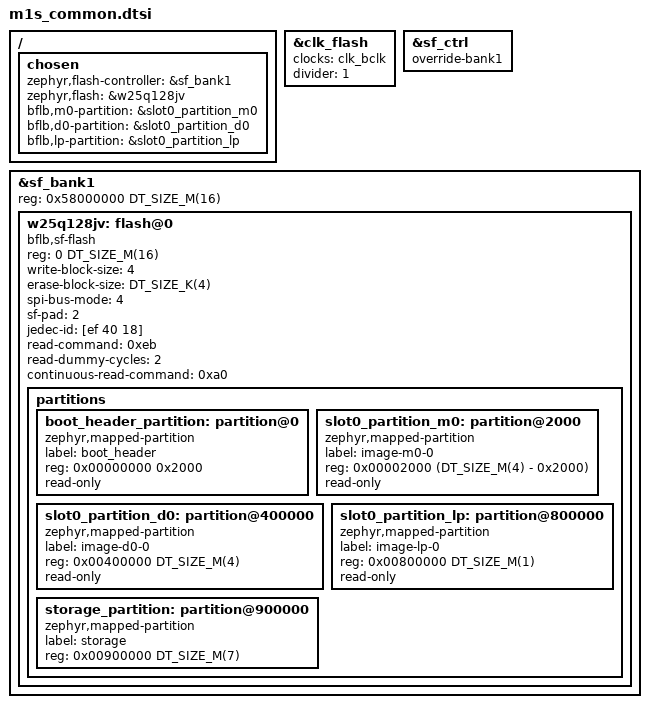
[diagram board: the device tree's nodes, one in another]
/*
 * Copyright The Zephyr Project Contributors
 *
 * SPDX-License-Identifier: Apache-2.0
 */

#include "m1s-pinctrl.dtsi"

/ {
	chosen {
		zephyr,flash-controller = &sf_bank1;
		zephyr,flash = &w25q128jv;
		bflb,m0-partition = &slot0_partition_m0;
		bflb,d0-partition = &slot0_partition_d0;
		bflb,lp-partition = &slot0_partition_lp;
	};
};

&clk_flash {
	clocks = <&clk_bclk>;
	divider = <1>;
};

&sf_ctrl {
	override-bank1;
};

&sf_bank1 {
	reg = <0x58000000 DT_SIZE_M(16)>;
	ranges = <0x0 0x58000000 DT_SIZE_M(16)>;

	w25q128jv: flash@0 {
		compatible = "bflb,sf-flash", "soc-nv-flash";
		reg = <0 DT_SIZE_M(16)>;
		ranges;
		#address-cells = <1>;
		#size-cells = <1>;
		write-block-size = <4>;
		erase-block-size = <DT_SIZE_K(4)>;

		spi-bus-mode = <4>;
		sf-pad = <2>;
		jedec-id = [ef 40 18];

		/* The flash equipped on M1S modules doesn't support useful SFDP, and the
		 * flash header doesn't provide a working configuration.
		 * Manually set configuration for best performance.
		 */
		read-command = <0xeb>;
		read-dummy-cycles = <2>;
		continuous-read-command = <0xa0>;

		partitions {
			ranges;
			#address-cells = <1>;
			#size-cells = <1>;

			boot_header_partition: partition@0 {
				compatible = "zephyr,mapped-partition";
				label = "boot_header";
				reg = <0x00000000 0x2000>;
				read-only;
			};

			slot0_partition_m0: partition@2000 {
				compatible = "zephyr,mapped-partition";
				label = "image-m0-0";
				reg = <0x00002000 (DT_SIZE_M(4) - 0x2000)>;
				read-only;
			};

			slot0_partition_d0: partition@400000 {
				compatible = "zephyr,mapped-partition";
				label = "image-d0-0";
				reg = <0x00400000 DT_SIZE_M(4)>;
				read-only;
			};

			slot0_partition_lp: partition@800000 {
				compatible = "zephyr,mapped-partition";
				label = "image-lp-0";
				reg = <0x00800000 DT_SIZE_M(1)>;
				read-only;
			};

			storage_partition: partition@900000 {
				compatible = "zephyr,mapped-partition";
				label = "storage";
				reg = <0x00900000 DT_SIZE_M(7)>;
			};
		};
	};
};
